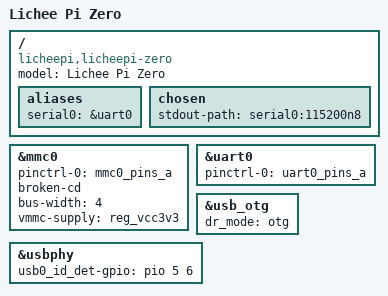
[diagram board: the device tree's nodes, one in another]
/dts-v1/;
#include "sun8i-v3s-uboot.dtsi"
#include "sunxi-common-regulators.dtsi"

/ {
	model = "Lichee Pi Zero";
	compatible = "licheepi,licheepi-zero", "allwinner,sun8i-v3s";

	aliases {
		serial0 = &uart0;
	};

	chosen {
		stdout-path = "serial0:115200n8";
	};
};

&mmc0 {
	pinctrl-0 = <&mmc0_pins_a>;
	pinctrl-names = "default";
	broken-cd;
	bus-width = <4>;
	vmmc-supply = <&reg_vcc3v3>;
	status = "okay";
};

&uart0 {
	pinctrl-0 = <&uart0_pins_a>;
	pinctrl-names = "default";
	status = "okay";
};

&usb_otg {
	dr_mode = "otg";
	status = "okay";
};

&usbphy {
	usb0_id_det-gpio = <&pio 5 6 GPIO_ACTIVE_HIGH>;
	status = "okay";
};
